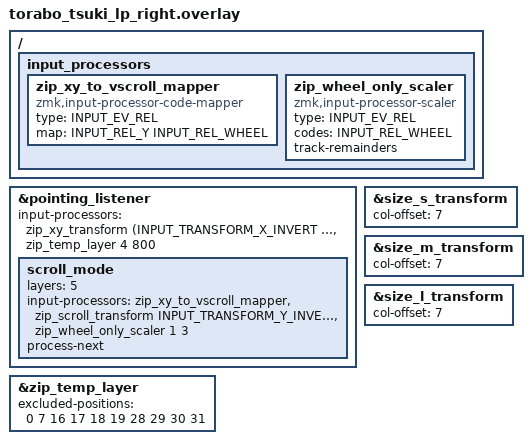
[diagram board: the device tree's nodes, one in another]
#include "torabo_tsuki_lp.dtsi"
#include <input/processors.dtsi>
#include <dt-bindings/zmk/input_transform.h>
#include <zephyr/dt-bindings/input/input-event-codes.h>

/ {
    input_processors {
        zip_xy_to_vscroll_mapper: zip_xy_to_vscroll_mapper {
            compatible = "zmk,input-processor-code-mapper";
            #input-processor-cells = <0>;
            type = <INPUT_EV_REL>;
            map = <INPUT_REL_Y INPUT_REL_WHEEL>;
        };

        zip_wheel_only_scaler: zip_wheel_only_scaler {
            compatible = "zmk,input-processor-scaler";
            #input-processor-cells = <2>;
            type = <INPUT_EV_REL>;
            codes = <INPUT_REL_WHEEL>;
            track-remainders;
        };
    };
};

&pointing_listener {
    scroll_mode {
        layers = <5>;
        input-processors = <
            &zip_xy_to_vscroll_mapper
            &zip_scroll_transform INPUT_TRANSFORM_Y_INVERT
            &zip_wheel_only_scaler 1 3
        >;
        process-next;
    };

    input-processors = <
        &zip_xy_transform (INPUT_TRANSFORM_X_INVERT | INPUT_TRANSFORM_Y_INVERT)
        &zip_temp_layer 4 800
    >;
};

&zip_temp_layer {
    excluded-positions = <0 7 16 17 18 19 28 29 30 31>;
};

&size_s_transform {
    col-offset = <7>;
};

&size_m_transform {
    col-offset = <7>;
};

&size_l_transform {
    col-offset = <7>;
};
